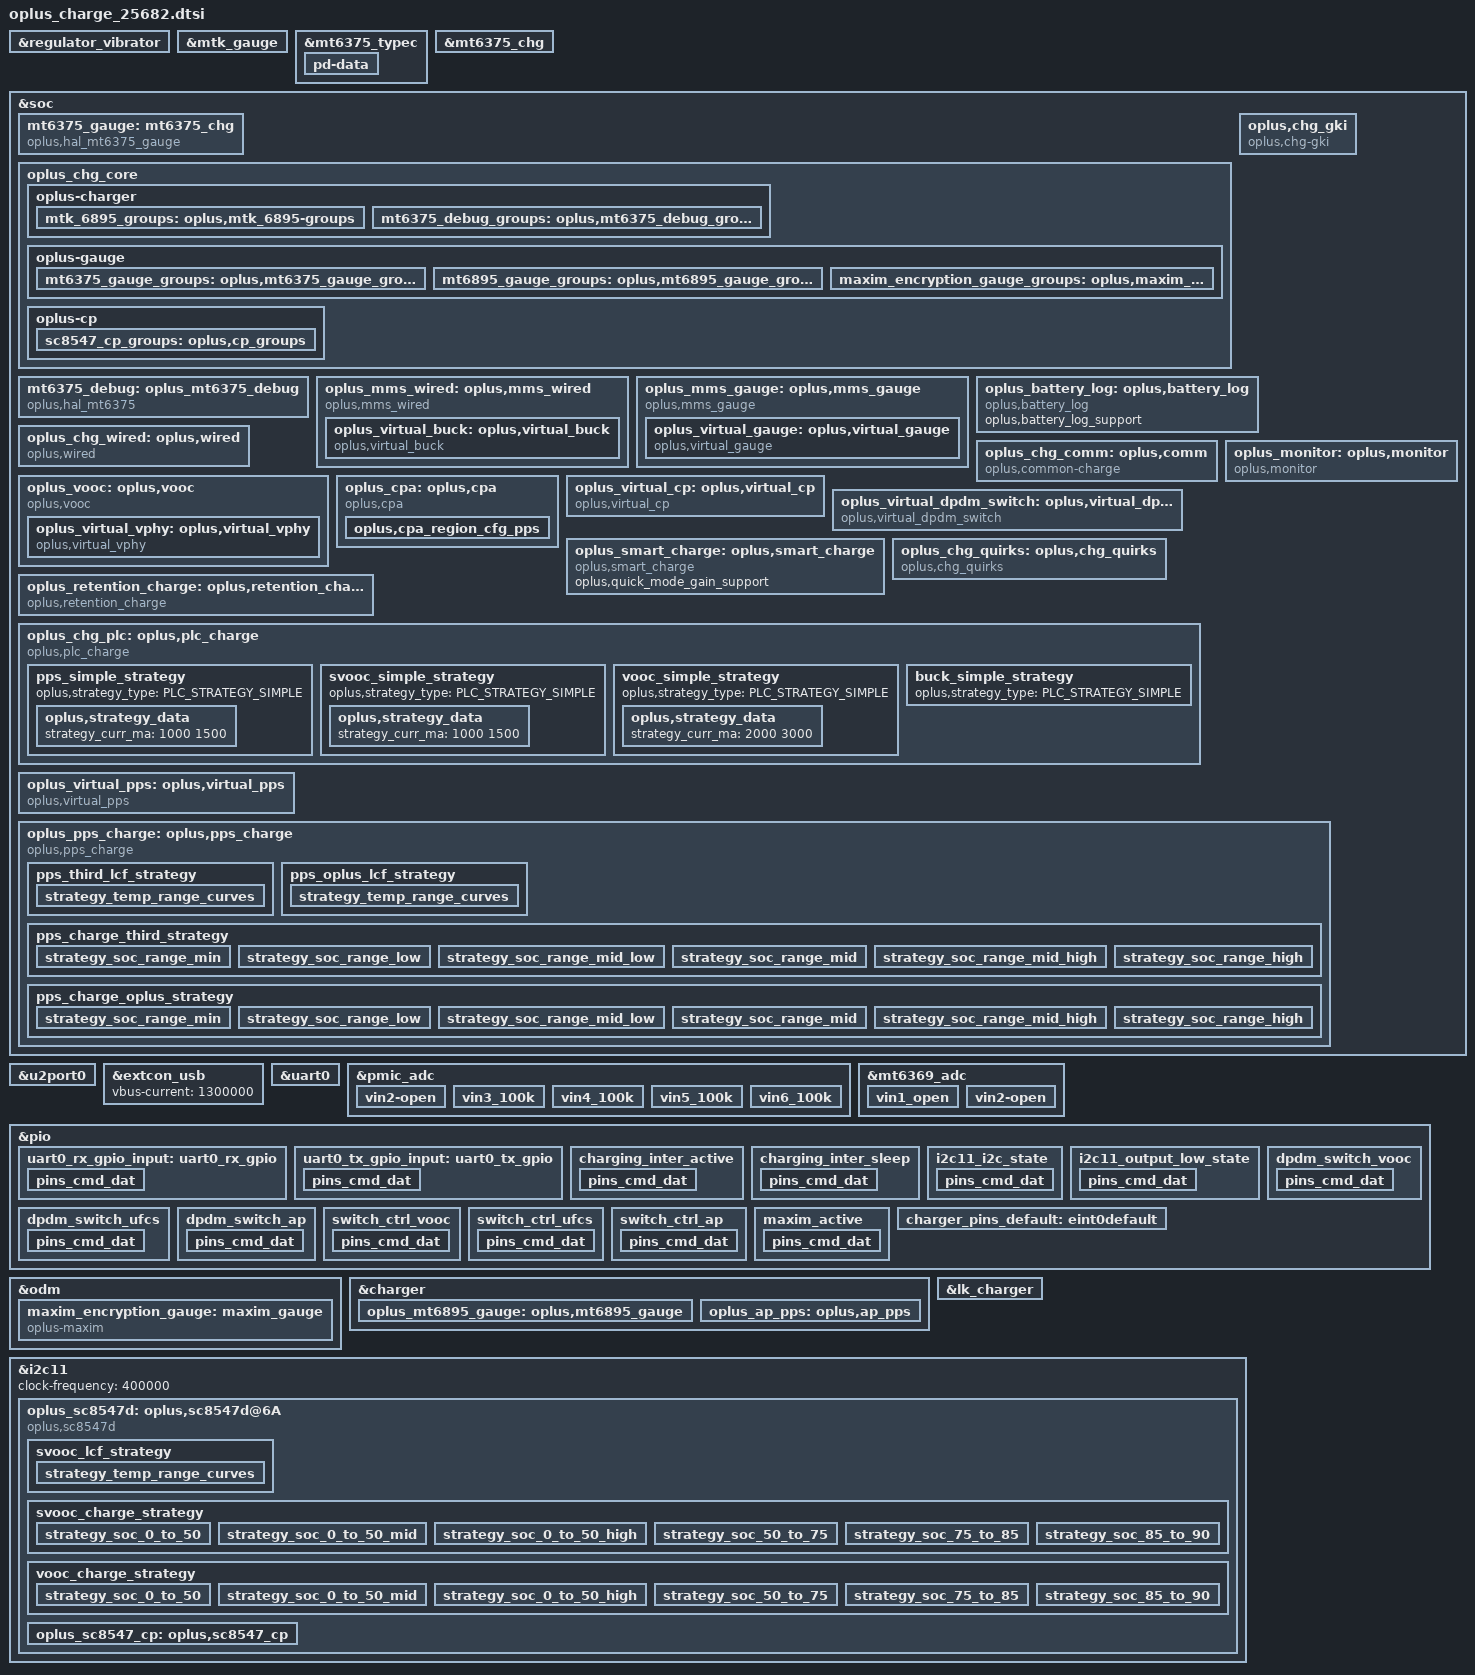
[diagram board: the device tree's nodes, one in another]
// SPDX-License-Identifier: GPL-2.0-only
/*
* Copyright (C) 2021-2020 Oplus. All rights reserved.
*/
#include <dt-bindings/iio/mt635x-auxadc.h>
#include <dt-bindings/iio/adc/mediatek,mt6375_auxadc.h>
#include <dt-bindings/pinctrl/mt6373-pinfunc.h>
#include <dt-bindings/pinctrl/mt65xx.h>
#include "oplus_chg.h"

/*
 *
 * CPU:MT6878 CHROME (export：CASIO-Y 24781，45W)
 *
 * UTXD0 -->GPIO48
 * URXD0 -->GPIO49
 *
 * I2C
 * MASTER_CHG --> I2C5 MT6375
 * CP_MASTER  --> I2C11 SC8547D
 * CP_SLAVE   --> I2C9 
 *
 * IRQB
 * EINT_CHG_1 (cp1 irq)               -->GPIO8
 * EINT_CHG_2 (cp2 irq)               -->GPIO9
 *
 * GPIO
 * VBUS_SHORT(防烧口)                 --> MT6369 MOS_CON1 H8
 * USB_SWITCH_1(usb/uart&vooc switch) --> GPIO44
 * USB_SWITCH_2(uart/vooc switch)     --> GPIO153
 * SEC_IC (加密电池GPIO for 80W)      --> GPIO43
 *
 * ADC:
 * MT6369 AUXADC_VIN1 				--> VBAT_BTB (Battery BTB)
 * MT6369 AUXADC_VIN2               --> NTC_USBCON_TEM (USB BTB)
 *
 * MT6363 AUXADC_VIN2				--> BAT_ID_ADC 电池ID
 * MT6363 AUXADC_VIN3				--> BATThermal_1 小板NTC
 * MT6363 AUXADC_VIN4				--> BB_USB_ADC1 防烧口NTC1
 * MT6363 AUXADC_VIN5				--> BB_USB_ADC2 防烧口NTC2
 * MT6363 AUXADC_VIN6				--> NTC_CHARGE (充电IC旁)
 *
 * BATTERY
 * BLT018 12200mAh double cells(NVT)  encrypted battery
 *
 */

/* charge start */
&regulator_vibrator{
	min-volt = <2800000>;
	max-volt = <2800000>;
};

&mtk_gauge {
	status = "okay";
	charger = <&mt6375_chg>;
	FUELGAGUE_APPLY = <(1)>;
	IS_SUBBOARD_TEMP_SUPPORT = <(0)>;
	EXTERNAL_AUTHENTICATE =<(1)>;
	Enable_Is_Force_Full = <(1)>;
	active-table = <(5)>;
	r-fg-value = <(2)>;/* R_sense resistance. 2 milliohm */
	com-r-fg-value = <(0)>;/* R_sense compensate resistance. not use COM_R_FG_VALUE */
	UNIT_MULTIPLE = <(1)>;
	RBAT_PULL_DOWN_R = <(24000)>;
	RBAT_PULL_UP_R = <(12000)>;
	RBAT_PULL_UP_VOLT = <(1840)>;
	USE_MORE_PRECISE_NTC_TABLE = <(1)>;
	car-tune-value = <(99)>;
	KEEP_100_PERCENT = <(1)>;
	SHUTDOWN_1_TIME = <(5)>;
	low-tmp-bat-voltage-low-bound1 = <(3350)>;
	com-fg-meter-resistance = <(40)>;

	io-channels = <&mt6375_auxadc MT6375_AUXADC_BATSNS>,
				  <&mt6375_auxadc MT6375_AUXADC_BATON>,
				  <&mt6375_auxadc MT6375_AUXADC_IMP>,
				  <&mt6375_auxadc MT6375_AUXADC_IMIX_R>,
				  <&mt6375_auxadc MT6375_AUXADC_VREF>,
				  <&pmic_adc (ADC_PURES_OPEN_MASK | AUXADC_VIN2)>;
	io-channel-names = "bat_volt", "bat_temp", "ptim_bat_volt",
					   "ptim_r", "vref", "auxadc5-batt_id_v";

	#include "bat_setting/mt6878_battery_prop_dim2_ext_25682_12200mAh_NVT.dtsi"
	#include "bat_setting/mt6878_battery_table_25682_12200mAh_NVT.dtsi"
};

&mt6375_typec {
	pd-data {
		pd,source-pdo-data = <0x00019082>; /* 5V, 1300 mA */
		pd,charging-policy = <0>;
	};
};

&mt6375_chg {
	ircmp_v = <0>;
	ircmp-r = <0>;
	chg-tmr = <15>;
};

&soc {
	mt6375_gauge: mt6375_chg {
		status = "okay";
		compatible = "oplus,hal_mt6375_gauge";

		oplus,ic_type = <OPLUS_CHG_IC_GAUGE>;
		oplus,ic_index = <0>;
		oplus,batt_num = <1>;
		oplus,mtk_gauge_power_sel_support;
		oplus,mtk_gauge_cali_track_support;
	};
};

&u2port0 {
	mediatek,eye-vrt = <7>;
	mediatek,eye-term = <7>;
	mediatek,rev6 = <3>;
	mediatek,eye-vrt-host = <7>;
	mediatek,eye-term-host = <7>;
	mediatek,rev6-host = <3>;
	mediatek,discth = <0x9>;
};

&extcon_usb {
	vbus-current = <1300000>;
};

&uart0 {
	pinctrl-names = "uart0_rx_gpio", "uart0_tx_gpio";
	pinctrl-0 = <&uart0_rx_gpio_input>;
	pinctrl-1 = <&uart0_tx_gpio_input>;
	status = "okay";
	txpin = <48>;
	rxpin = <49>;
};

&pmic_adc {
	vin2-open {
		channel = <AUXADC_VIN2>;
		pures = <ADC_PURES_OPEN>;
	};
	vin3_100k {
		channel = <AUXADC_VIN3>;
		pures = <ADC_PURES_100K>;
	};
	vin4_100k {
		channel = <AUXADC_VIN4>;
		pures = <ADC_PURES_100K>;
	};
	vin5_100k {
		channel = <AUXADC_VIN5>;
		pures = <ADC_PURES_100K>;
	};
	vin6_100k {
		channel = <AUXADC_VIN6>;
		pures = <ADC_PURES_100K>;
	};
};

&mt6369_adc {
    vin1_open {
		channel = <AUXADC_VIN1>;
		pures = <ADC_PURES_OPEN>;
    };
	vin2-open {
		channel = <AUXADC_VIN2>;
		pures = <ADC_PURES_OPEN>;
	};
};

&pio {
	uart0_rx_gpio_input: uart0_rx_gpio {
		pins_cmd_dat {
			pinmux = <PINMUX_GPIO49__FUNC_GPIO49>; /* URXD0 */
			input-enable;
			bias-disable;
		};
	};

	uart0_tx_gpio_input: uart0_tx_gpio {
		pins_cmd_dat {
			pinmux = <PINMUX_GPIO48__FUNC_GPIO48>; /* UTXD0 */
			input-enable;
			bias-disable;
		};
	};

	charging_inter_active: charging_inter_active {
		pins_cmd_dat {
			pinmux = <PINMUX_GPIO8__FUNC_GPIO8>;
			input-enable;
			bias-pull-up;
		};
	};

	charging_inter_sleep: charging_inter_sleep {
		pins_cmd_dat {
			pinmux = <PINMUX_GPIO8__FUNC_GPIO8>;
			input-enable;
			bias-pull-up;
		};
	};

	i2c11_i2c_state: i2c11_i2c_state {
		pins_cmd_dat {
			pinmux = <PINMUX_GPIO148__FUNC_SDA11>,
				 <PINMUX_GPIO147__FUNC_SCL11>;
			bias-disable;
		};
	};

	i2c11_output_low_state: i2c11_output_low_state {
		pins_cmd_dat {
			pinmux = <PINMUX_GPIO148__FUNC_GPIO148>,
				 <PINMUX_GPIO147__FUNC_GPIO147>;
			output-low;
		};
	};

	dpdm_switch_vooc: dpdm_switch_vooc {
		pins_cmd_dat {
			pinmux = <PINMUX_GPIO44__FUNC_GPIO44>;
			output-high;
		};
 	};

 	dpdm_switch_ufcs: dpdm_switch_ufcs {
 		pins_cmd_dat {
			pinmux = <PINMUX_GPIO44__FUNC_GPIO44>;
			output-high;
		};
 	};

 	dpdm_switch_ap: dpdm_switch_ap {
 		pins_cmd_dat {
			pinmux = <PINMUX_GPIO44__FUNC_GPIO44>;
			output-low;
		};
 	};

 	switch_ctrl_vooc: switch_ctrl_vooc {
 		pins_cmd_dat {
			pinmux = <PINMUX_GPIO153__FUNC_GPIO153>;
			output-high;
		};
 	};

 	switch_ctrl_ufcs: switch_ctrl_ufcs {
 		pins_cmd_dat {
			pinmux = <PINMUX_GPIO153__FUNC_GPIO153>;
			output-high;
		};
 	};

 	switch_ctrl_ap: switch_ctrl_ap {
 		pins_cmd_dat {
			pinmux = <PINMUX_GPIO153__FUNC_GPIO153>;
			output-low;
		};
 	};

	maxim_active: maxim_active {
		pins_cmd_dat {
			pinmux = <PINMUX_GPIO43__FUNC_GPIO43>;
			drive-strength = <6>;
			bias-pull-up;
		};
	};

	charger_pins_default: eint0default {
	};
};

&soc {
	oplus_chg_core {
		oplus,chg_framework_v2;
		oplus,smart_charging_screenoff;
		oplus,chg_spec_version = <OPLUS_CHG_SPEC_VER_V3P7>;
		oplus,common-charge-icl-support;
		oplus-charger {
			mtk_6895_groups: oplus,mtk_6895-groups {
				functions = <
					OPLUS_IC_FUNC_INIT
					OPLUS_IC_FUNC_EXIT
					OPLUS_IC_FUNC_REG_DUMP
					OPLUS_IC_FUNC_SMT_TEST
					OPLUS_IC_FUNC_BUCK_INPUT_PRESENT
					OPLUS_IC_FUNC_BUCK_INPUT_SUSPEND
					OPLUS_IC_FUNC_BUCK_INPUT_IS_SUSPEND
					OPLUS_IC_FUNC_BUCK_OUTPUT_SUSPEND
					OPLUS_IC_FUNC_BUCK_OUTPUT_IS_SUSPEND
					OPLUS_IC_FUNC_BUCK_SET_ICL
					OPLUS_IC_FUNC_BUCK_GET_ICL
					OPLUS_IC_FUNC_BUCK_SET_FCC
					OPLUS_IC_FUNC_BUCK_SET_FV
					OPLUS_IC_FUNC_BUCK_SET_ITERM
					OPLUS_IC_FUNC_BUCK_GET_INPUT_CURR
					OPLUS_IC_FUNC_BUCK_GET_INPUT_VOL
					OPLUS_IC_FUNC_OTG_BOOST_ENABLE
					OPLUS_IC_FUNC_BUCK_GET_CC_ORIENTATION
					OPLUS_IC_FUNC_BUCK_GET_CHARGER_TYPE
					OPLUS_IC_FUNC_BUCK_RERUN_BC12
					OPLUS_IC_FUNC_BUCK_QC_DETECT_ENABLE
					OPLUS_IC_FUNC_BUCK_SET_QC_CONFIG
					OPLUS_IC_FUNC_BUCK_SET_PD_CONFIG
					OPLUS_IC_FUNC_GET_SHUTDOWN_SOC
					OPLUS_IC_FUNC_BACKUP_SOC
					OPLUS_IC_FUNC_GET_TYPEC_MODE
					OPLUS_IC_FUNC_SET_TYPEC_MODE
					OPLUS_IC_FUNC_GET_TYPEC_ROLE
					OPLUS_IC_FUNC_GET_OTG_ENABLE
					OPLUS_IC_FUNC_BUCK_GET_HW_DETECT
					OPLUS_IC_FUNC_SET_USB_DISCHG_ENABLE
					OPLUS_IC_FUNC_GET_USB_DISCHG_STATUS
					OPLUS_IC_FUNC_IS_OPLUS_SVID
					OPLUS_IC_FUNC_BUCK_GET_USB_BTB_TEMP
					OPLUS_IC_FUNC_BUCK_GET_BATT_BTB_TEMP
					OPLUS_IC_FUNC_BUCK_SHIPMODE_ENABLE
					OPLUS_IC_FUNC_BUCK_SET_AICL_POINT
					OPLUS_IC_FUNC_SET_OTG_BOOST_CURR_LIMIT
					OPLUS_IC_FUNC_BUCK_GET_FV
					OPLUS_IC_FUNC_BUCK_GET_TYPEC_STATE
				>;
				virqs = <
					OPLUS_IC_VIRQ_ERR
					OPLUS_IC_VIRQ_CC_DETECT
					OPLUS_IC_VIRQ_PLUGIN
					OPLUS_IC_VIRQ_CC_CHANGED
					OPLUS_IC_VIRQ_CHG_TYPE_CHANGE
					OPLUS_IC_VIRQ_OTG_ENABLE
					OPLUS_IC_VIRQ_SVID
					OPLUS_IC_VIRQ_TYPEC_STATE
				>;
			};


			mt6375_debug_groups: oplus,mt6375_debug_groups {
				functions = <
					OPLUS_IC_FUNC_INIT
					OPLUS_IC_FUNC_EXIT
				>;
				virqs = <
					OPLUS_IC_VIRQ_ERR
				>;
			};
		};

		oplus-gauge {
			mt6375_gauge_groups: oplus,mt6375_gauge_groups {
				functions = <
					OPLUS_IC_FUNC_INIT
					OPLUS_IC_FUNC_EXIT
					OPLUS_IC_FUNC_REG_DUMP
					OPLUS_IC_FUNC_SMT_TEST
					OPLUS_IC_FUNC_GAUGE_GET_BATT_VOL
					OPLUS_IC_FUNC_GAUGE_GET_BATT_MAX
					OPLUS_IC_FUNC_GAUGE_GET_BATT_MIN
					OPLUS_IC_FUNC_GAUGE_GET_BATT_CURR
					OPLUS_IC_FUNC_GAUGE_GET_BATT_TEMP
					OPLUS_IC_FUNC_GAUGE_GET_BATT_SOC
					OPLUS_IC_FUNC_GAUGE_GET_BATT_FCC
					OPLUS_IC_FUNC_GAUGE_GET_BATT_CC
					OPLUS_IC_FUNC_GAUGE_GET_BATT_RM
					OPLUS_IC_FUNC_GAUGE_GET_BATT_SOH
					OPLUS_IC_FUNC_GAUGE_GET_BATT_HMAC
					OPLUS_IC_FUNC_GAUGE_SET_BATT_FULL
					OPLUS_IC_FUNC_GAUGE_UPDATE_DOD0
					OPLUS_IC_FUNC_GAUGE_UPDATE_SOC_SMOOTH
					OPLUS_IC_FUNC_GAUGE_GET_CB_STATUS
					OPLUS_IC_FUNC_GAUGE_GET_BATT_NUM
					OPLUS_IC_FUNC_GAUGE_GET_DEVICE_TYPE
					OPLUS_IC_FUNC_GAUGE_GET_DEVICE_TYPE_FOR_VOOC
					OPLUS_IC_FUNC_GAUGE_GET_BATT_FCC
					OPLUS_IC_FUNC_GAUGE_GET_BATT_FC
					OPLUS_IC_FUNC_GAUGE_GET_BATT_QM
					OPLUS_IC_FUNC_GAUGE_GET_BATT_PD
					OPLUS_IC_FUNC_GAUGE_GET_BATT_RCU
					OPLUS_IC_FUNC_GAUGE_GET_BATT_RCF
					OPLUS_IC_FUNC_GAUGE_GET_BATT_FCU
					OPLUS_IC_FUNC_GAUGE_GET_BATT_FCF
					OPLUS_IC_FUNC_GAUGE_GET_BATT_SOU
					OPLUS_IC_FUNC_GAUGE_GET_BATT_DO0
					OPLUS_IC_FUNC_GAUGE_GET_BATT_DOE
					OPLUS_IC_FUNC_GAUGE_GET_BATT_TRM
					OPLUS_IC_FUNC_GAUGE_GET_BATT_PC
					OPLUS_IC_FUNC_GAUGE_GET_BATT_QS
					OPLUS_IC_FUNC_GAUGE_IS_SUSPEND
					OPLUS_IC_FUNC_GAUGE_GET_BCC_PARMS
					OPLUS_IC_FUNC_GAUGE_FASTCHG_UPDATE_BCC_PARMS
					OPLUS_IC_FUNC_GAUGE_GET_PREV_BCC_PARMS
					OPLUS_IC_FUNC_GAUGE_SET_BCC_PARMS
					OPLUS_IC_FUNC_GAUGE_SET_PROTECT_CHECK
					OPLUS_IC_FUNC_GAUGE_GET_AFI_UPDATE_DONE
					OPLUS_IC_FUNC_GAUGE_CHECK_RESET
					OPLUS_IC_FUNC_GAUGE_GET_DEVICE_TYPE_FOR_BCC
					OPLUS_IC_FUNC_GAUGE_GET_DOD0
					OPLUS_IC_FUNC_GAUGE_GET_DOD0_PASSED_Q
					OPLUS_IC_FUNC_GAUGE_GET_QMAX
					OPLUS_IC_FUNC_GAUGE_GET_QMAX_PASSED_Q
					OPLUS_IC_FUNC_GAUGE_SET_BATTERY_CURVE
					OPLUS_IC_FUNC_GAUGE_GET_DEC_FG_TYPE
					OPLUS_IC_FUNC_GAUGE_GET_DEC_CV_SOH
				>;
				virqs = <
					OPLUS_IC_VIRQ_ERR
					OPLUS_IC_VIRQ_OFFLINE
					OPLUS_IC_VIRQ_RESUME
				>;
			};

			mt6895_gauge_groups: oplus,mt6895_gauge_groups {
				functions = <
					OPLUS_IC_FUNC_INIT
					OPLUS_IC_FUNC_EXIT
					OPLUS_IC_FUNC_GAUGE_GET_SUBBOARD_TEMP
				>;
				virqs = <
					OPLUS_IC_VIRQ_ERR
				>;
			};

			maxim_encryption_gauge_groups: oplus,maxim_encryption_gauge_groups {
				functions = <
					OPLUS_IC_FUNC_INIT
					OPLUS_IC_FUNC_EXIT
					OPLUS_IC_FUNC_GAUGE_GET_BATT_AUTH
				>;
				virqs = <
					OPLUS_IC_VIRQ_ERR
				>;
			};
		};
		oplus-cp {
			sc8547_cp_groups: oplus,cp_groups {
			functions = <
					OPLUS_IC_FUNC_INIT
					OPLUS_IC_FUNC_EXIT
					OPLUS_IC_FUNC_REG_DUMP
					OPLUS_IC_FUNC_SMT_TEST
					OPLUS_IC_FUNC_CP_ENABLE
					OPLUS_IC_FUNC_CP_HW_INTI
					OPLUS_IC_FUNC_CP_SET_WORK_START
					OPLUS_IC_FUNC_CP_CHECK_WORK_MODE_SUPPORT
					OPLUS_IC_FUNC_CP_SET_WORK_MODE
					OPLUS_IC_FUNC_CP_GET_WORK_MODE
					OPLUS_IC_FUNC_CP_GET_VIN
					OPLUS_IC_FUNC_CP_GET_IIN
					OPLUS_IC_FUNC_CP_SET_IIN
					OPLUS_IC_FUNC_CP_GET_VOUT
					OPLUS_IC_FUNC_CP_GET_IOUT
					OPLUS_IC_FUNC_CP_GET_VAC
					OPLUS_IC_FUNC_CP_GET_WORK_STATUS
					OPLUS_IC_FUNC_CP_SET_ADC_ENABLE
					OPLUS_IC_FUNC_CP_WATCHDOG_ENABLE
					OPLUS_IC_FUNC_CP_SET_UCP_DISABLE
				>;
				virqs = <
					OPLUS_IC_VIRQ_ERR
					OPLUS_IC_VIRQ_ONLINE
					OPLUS_IC_VIRQ_OFFLINE
				>;
			};
		};
	};
};

&soc {
	mt6375_debug: oplus_mt6375_debug {
		status = "okay";
		compatible = "oplus,hal_mt6375";
		oplus,tcpc_name = "type_c_port0";
		oplus,ic_type = <OPLUS_CHG_IC_BUCK>;
		oplus,ic_index = <2>;
	};
};

/*
* chrome secbat sn
* 6113 0700 0087
* 6113 0700 0088
* 6129 0300 0144
* 6113 0300 0213
*/
&odm {
	maxim_encryption_gauge: maxim_gauge {
		status = "okay";
		compatible = "oplus-maxim";
		pinctrl-names = "maxim_active";
		pinctrl-0 = <&maxim_active>;
		support_encryption_in_lk;
		data-gpio = <&pio 43 0x00>;
		gpio-addr-set-out = <0x10005014>;
		gpio-addr-set-in = <0x10005018>;
		gpio-addr-level_high = <0x10005114>;
		gpio-addr-level_low = <0x10005118>;
		gpio-addr-data-in = <0x10005210>;
		gpio-addr-offset = <0x0b>;
		oplus,batt_info = /bits/ 8 <0x36 0x31 0x31 0x33 0x30 0x37 0x30 0x30 0x30 0x30 0x38 0x37
		                            0x36 0x31 0x31 0x33 0x30 0x37 0x30 0x30 0x30 0x30 0x38 0x38
		                            0x36 0x31 0x32 0x39 0x30 0x33 0x30 0x30 0x30 0x31 0x34 0x34
		                            0x36 0x31 0x31 0x33 0x30 0x33 0x30 0x30 0x30 0x32 0x31 0x33>;
		oplus,ic_type = <OPLUS_CHG_IC_GAUGE>;
		oplus,ic_index = <2>;
	};
};

&soc {
	oplus,chg_gki {
		compatible = "oplus,chg-gki";
	};
};

&charger {
	io-channels = <&mt6369_adc (ADC_PURES_OPEN_MASK | AUXADC_VIN1)>, <&mt6369_adc (ADC_PURES_OPEN_MASK | AUXADC_VIN2)>, <&pmic_adc AUXADC_VIN6>, <&pmic_adc AUXADC_VIN3>;
	io-channel-names = "auxadc5_batt_btb_temp", "auxadc6_usb_btb_temp", "auxadc5-chargeric_temp", "auxadc1-ntc_sub_bat_tem";

	pinctrl-names = "default";
	pinctrl-0 = <&charger_pins_default>;
	oplus,support_ntc_01c_precision;
	max_charger_voltage = <15000000>;
	oplus,ntc_temp_volt_1840mv;
	oplus,force_use_4250K_ntc;

	/* usbtemp dischg use pmic regulator to set vbus down */
	oplus,support_usbtemp_dischg_reg_configurable;
	oplus,usbtemp_dischg_reg_addr = <0x989>;
	oplus,usbtemp_dischg_reg_mask = <0x7>;
	oplus,usbtemp_dischg_enable = <0x2>;
	oplus,usbtemp_dischg_disable = <0x0>;

	oplus,ic_type = <OPLUS_CHG_IC_BUCK>;
	oplus,ic_index = <0>;

	oplus_mt6895_gauge: oplus,mt6895_gauge {
		oplus,ic_type = <OPLUS_CHG_IC_GAUGE>;
		oplus,ic_index = <1>;
	};
};

&lk_charger {
	en_vol_ctrl_vibrate = <3200>;
	support_tuv_authentication;
	high-temp-scheme;
	charger_no_wiress;
	support_battery_type = <2>;
	support_maxim_battery_authentication;
	data-gpio = <43>;
	oplus,batt_info = /bits/ 8 <0x36 0x31 0x31 0x33 0x30 0x37 0x30 0x30 0x30 0x30 0x38 0x37
		                        0x36 0x31 0x31 0x33 0x30 0x37 0x30 0x30 0x30 0x30 0x38 0x38
		                        0x36 0x31 0x32 0x39 0x30 0x33 0x30 0x30 0x30 0x31 0x34 0x34
		                        0x36 0x31 0x31 0x33 0x30 0x33 0x30 0x30 0x30 0x32 0x31 0x33>;

	support_sdp_screenoff;
	support_sdp_backlight;
	sdp_screenon_voltage = <3250>;
	support_quickboot_charge;
	over_high_temp_thr = <60>;
	led-brightness = <102>;
	max-charger-voltage = <15000000>;
	boot-battery-voltage = <3350000>;
	usb-charger-current = <500000>;
	ac-charger-current = <2050000>;
	ac-charger-input-current = <1500000>;
	non-std-ac-charger-current = <750000>;
	charging-host-charger-current = <1500000>;
	ta-ac-charger-current = <1500000>;
	pd-charger-current = <500000>;
};

&soc {
	oplus_mms_wired: oplus,mms_wired {
		compatible = "oplus,mms_wired";
		oplus,buck_ic = <&oplus_virtual_buck>;
		oplus,voocphy_ic = <&oplus_virtual_vphy>;
		oplus,adc_info_name = "100k_1840mv";
		oplus_spec,usbtemp_batttemp_gap = <12>;

		/* support for V2.0 usbtemp protect. */
		high-temp-scheme;
		oplus,support_usbtemp_protect_v2;
		oplus_spec,usbtemp_batt_temp_low = <50>;
		oplus_spec,usbtemp_batt_temp_high = <50>;
		oplus_spec,usbtemp_batt_temp_over_hot = <60>;
		oplus_spec,usbtemp_ntc_temp_low = <57>;
		oplus_spec,usbtemp_ntc_temp_high = <69>;
		oplus_spec,usbtemp_temp_gap_low_with_batt_temp = <7>;
		oplus_spec,usbtemp_temp_gap_with_batt_temp_in_over_hot = <15>;
		oplus_spec,usbtemp_temp_gap_high_with_batt_temp = <12>;
		oplus_spec,usbtemp_temp_gap_low_without_batt_temp = <12>;
		oplus_spec,usbtemp_temp_gap_high_without_batt_temp = <24>;
		oplus_spec,usbtemp_rise_fast_temp_low = <3>;
		oplus_spec,usbtemp_rise_fast_temp_high = <3>;
		oplus_spec,usbtemp_rise_fast_temp_count_low = <30>;
		oplus_spec,usbtemp_rise_fast_temp_count_high = <20>;
		oplus_spec,usbtemp_cool_down_ntc_low = <54>;
		oplus_spec,usbtemp_cool_down_ntc_high = <65>;
		oplus_spec,usbtemp_cool_down_gap_low = <12>;
		oplus_spec,usbtemp_cool_down_gap_high = <20>;
		oplus_spec,usbtemp_cool_down_recover_ntc_low = <48>;
		oplus_spec,usbtemp_cool_down_recover_ntc_high = <60>;
		oplus_spec,usbtemp_cool_down_recover_gap_low = <6>;
		oplus_spec,usbtemp_cool_down_recover_gap_high = <15>;
		oplus_spec,usbtemp_otg_cc_boot_current_limit = <1300000>;

		oplus_virtual_buck: oplus,virtual_buck {
			compatible = "oplus,virtual_buck";
			oplus,buck_ic = <&charger &mt6375_debug>;
			oplus,buck_ic_index = <0 1>;
			oplus,buck_ic_current_ratio = <100 0>;
			oplus,buck_ic_connect = <OPLUS_CHG_IC_CONNECT_PARALLEL>;
			oplus,main_charger = <0>;
			oplus,buck_ic_func_group = <&mtk_6895_groups &mt6375_debug_groups>;

			oplus,ic_type = <OPLUS_CHG_IC_VIRTUAL_BUCK>;
			oplus,ic_index = <0>;

			io-channels = <&pmic_adc AUXADC_VIN4>, <&pmic_adc AUXADC_VIN5>;
			io-channel-names = "usb_temp_adc_l", "usb_temp_adc_r";

			oplus,uart_tx-gpio = <&pio 48 0x00>;
			oplus,uart_rx-gpio = <&pio 49 0x00>;
		};
	};

	oplus_mms_gauge: oplus,mms_gauge {
		compatible = "oplus,mms_gauge";
		oplus,gauge_ic = <&oplus_virtual_gauge>;
		oplus,voocphy_ic = <&oplus_virtual_vphy>;
		oplus,topic-update-interval = <10000>;

		oplus_virtual_gauge: oplus,virtual_gauge {
			compatible = "oplus,virtual_gauge";
			oplus,gauge_ic = <&mt6375_gauge &oplus_mt6895_gauge &maxim_encryption_gauge>;
			oplus,gauge_ic_index = <0 1 2>;
			oplus,gauge_ic_func_group = <&mt6375_gauge_groups &mt6895_gauge_groups &maxim_encryption_gauge_groups>;
			oplus,batt_capacity_mah = <12200>;
			oplus,ic_type = <OPLUS_CHG_IC_VIRTUAL_GAUGE>;
			oplus,ic_index = <0>;
		};
	};
};

&soc {
	oplus_battery_log: oplus,battery_log {
		compatible = "oplus,battery_log";
		oplus,battery_log_support;
	};

	oplus_chg_wired: oplus,wired {
		compatible = "oplus,wired";

		oplus,vooc-support;
		oplus_spec,vbatt_pdqc_to_5v_thr = <4490>;
		oplus_spec,vbatt_pdqc_to_9v_thr = <4500>;
		oplus_spec,pd-iclmax-ma = <1500>;
		oplus_spec,qc-iclmax-ma = <1500>;
		oplus_spec,non-standard-ibatmax-ma = <500>;
		oplus_spec,input-power-mw = <
			2500		/* OPLUS_WIRED_CHG_MODE_UNKNOWN */
			2500		/* OPLUS_WIRED_CHG_MODE_SDP */
			7500		/* OPLUS_WIRED_CHG_MODE_CDP */
			10000		/* OPLUS_WIRED_CHG_MODE_DCP */
			15000		/* OPLUS_WIRED_CHG_MODE_VOOC */
			13500		/* OPLUS_WIRED_CHG_MODE_QC */
			13500		/* OPLUS_WIRED_CHG_MODE_PD */
		>;
		oplus_spec,led_on-fccmax-ma = <0 1140 4000 4000 4000 4000 4000 1000 0>;
		oplus_spec,fccmax-ma-lv = <
			0 600   2200 2200 2200 2200 2200 2200 0	/* OPLUS_WIRED_CHG_MODE_UNKNOWN */
			0 600   600  600  600  600  600  600  0	/* OPLUS_WIRED_CHG_MODE_SDP */
			0 600   1600 1600 1600 1600 1600 1600 0	/* OPLUS_WIRED_CHG_MODE_CDP */
			0 600   2200 2200 2200 2200 2200 2200 0	/* OPLUS_WIRED_CHG_MODE_DCP */
			0 600   3000 3000 3000 3000 3000 2200 0	/* OPLUS_WIRED_CHG_MODE_VOOC */
			0 600   3300 3300 3300 3300 3300 3300 0	/* OPLUS_WIRED_CHG_MODE_QC */
			0 600   3300 3300 3300 3300 3300 3300 0	/* OPLUS_WIRED_CHG_MODE_PD */
		>;
		oplus_spec,fccmax-ma-hv = <
			0 600   2200 2200 2200 2200 2200 2200 0	/* OPLUS_WIRED_CHG_MODE_UNKNOWN */
			0 600   600  600  600  600  600  600  0	/* OPLUS_WIRED_CHG_MODE_SDP */
			0 600   1600 1600 1600 1600 1600 1600 0	/* OPLUS_WIRED_CHG_MODE_CDP */
			0 600   2200 2200 2200 2200 2200 2200 0	/* OPLUS_WIRED_CHG_MODE_DCP */
			0 600   3000 3000 3000 3000 3000 2200 0	/* OPLUS_WIRED_CHG_MODE_VOOC */
			0 600   3300 3300 3300 3300 3300 3300 0	/* OPLUS_WIRED_CHG_MODE_QC */
			0 600   3300 3300 3300 3300 3300 3300 0	/* OPLUS_WIRED_CHG_MODE_PD */
		>;
		oplus_spec,cool_down_sale_pdqc_vol_mv = <5000>;
		oplus_spec,cool_down_pdqc_vol_mv = <5000 5000 5000 9000>;
		oplus_spec,cool_down_pdqc_curr_ma = <1200 1500 2000 1500>;
		oplus_spec,cool_down_vooc_curr_ma = <1200 1500 2000 2500 3000 3000>;
		oplus_spec,cool_down_normal_curr_ma = <1200 1500 2000>;

		oplus_spec,vbus_ov_thr_mv = <10500 10500>;
		oplus_spec,vbus_uv_thr_mv = <4300 4300>;

		oplus,pd_strategy_name = "cgcl";
		oplus,pd_strategy_data = <OPLUS_STRATEGY_USE_SHELL_TEMP
					    0   420 2000 1 0
					    420 430 1500 2 0
					    450 440 1200 2 1>;
		oplus,qc_strategy_name = "cgcl";
		oplus,qc_strategy_data = <OPLUS_STRATEGY_USE_SHELL_TEMP
					    0   420 2000 1 0
					    410 430 1500 2 0
					    420 440 1200 2 1>;
	};

	oplus_chg_comm: oplus,comm {
		compatible = "oplus,common-charge";
		oplus_spec,dec_step = <20>;
		oplus_spec,dec-vol-cc-full-thr = <0 400 600 800 1000 1200>;
		oplus_spec,dec-vol-fv-full-mv = <0 20 20 40 40 40>;
		oplus_spec,batt-them-thr = <(-100) 0 50 120 160 350 450 530>;
		oplus_spec,iterm-ma = <605>; /* 12200*0.05+10 */
		oplus_spec,removed_bat_decidegc = <390>; /*-39 degree*/
		oplus_spec,fv-mv = <4490 4490 4490 4490 4490 4490 4470 4130 4130>;
		oplus_spec,sw-fv-mv = <4440 4440 4440 4440 4440 4440 4420 4080 4080>;
		oplus_spec,hw-fv-inc-mv = <0 18 18 18 18 18 18 18 0>;
		oplus_spec,sw-over-fv-mv = <4500 4500 4500 4500 4500 4500 4480 4140 4140>;
		oplus_spec,sw-over-fv-dec-mv = <8>;
		oplus_spec,non-standard-sw-fv-mv = <3930>;
		oplus_spec,non-standard-fv-mv = <3980>;
		oplus_spec,non-standard-hw-fv-inc-mv = <18>;
		oplus_spec,non-standard-sw-over-fv-mv = <3990>;
		oplus_spec,non-standard-vbatdet-mv = <3680>;
		oplus_spec,wired-vbatdet-mv = <0 4190 4290 4390 4390 4390 4370 4030 0>;
		oplus_spec,fcc-gear-thr-mv = <4180>;
		oplus_spec,vbatt-ov-thr-mv = <4600>;

		oplus_spec,full_pre_ffc_judge;
		oplus_spec,full-pre-ffc-mv = <4485>;
		oplus_spec,ffc-temp-thr = <120 210 350 440>;
		oplus_spec,wired-ffc-step-max = <2>;
		oplus_spec,wired-ffc-fv-mv = <4630 4630>;

		oplus_spec,wired-ffc-fv-cutoff-mv = <4494 4494 4474 4484 4484 4465>;
		oplus_spec,wired-ffc-fcc-ma = <1500 1500 1500 1000 1000 1000>;
		oplus_spec,wired-ffc-fcc-cutoff-ma = <1300 1300 1300 900 900 900>;
		oplus_spec,vbat_uv_thr_mv = <3300>;
		oplus_spec,vbat_charging_uv_thr_mv = <3200>;

		/*If use subboard NTC as battery temp, config it as 20, otherwise 0 */
		oplus_spec,tbatt_power_off_cali_temp = <0>;
		oplus_spec,poweroff_high_batt_temp = <720>;
		oplus_spec,poweroff_emergency_batt_temp = <770>;
		oplus,vooc_show_ui_soc_decimal;
		oplus,ui_soc_decimal_speedmin = <20>;
		oplus,gauge_stuck_jump_support;
		oplus,gauge_stuck_threshold = <15>;
		oplus,gauge_stuck_time = <50>;
		oplus,smooth_switch;
		oplus,reserve_chg_soc = <2>;
	};

	oplus_monitor: oplus,monitor {
		compatible = "oplus,monitor";
		oplus,topic-update-interval = <60000>;

		track,fast_chg_break_t_thd = <1000>;
		track,general_chg_break_t_thd = <200>;
		track,voocphy_type = <2>;
		track,wired_max_power = <45000>;
		track,wired_fast_chg_scheme = <2>;
	};

	oplus_vooc: oplus,vooc {
		compatible = "oplus,vooc";
		oplus,vooc_ic = <&oplus_virtual_vphy>;
		oplus_spec,vooc_soc_range = <50 75 85>;
		oplus,vooc_data_width = <7>;
		oplus,vooc_curr_max = <CP_CURR_LIMIT_7BIT_9_0A>; /* 45W: 11V 7.3A(IBUS *2) */
		oplus,vooc_power_max_w = <45>;
		oplus,vooc_project = <21>;
		oplus,vooc_curr_table_type = <VOOC_CP_CURR_TABLE>;
		oplus,voocphy_support = <2>; /* AP_SINGLE_CP_VOOCPHY */
		oplus,support_fake_vooc_check;
		oplus,subboard_ntc_abnormal_current = <4000>;

		oplus,abnormal_adapter_current = <CURR_LIMIT_7BIT_7_5A CURR_LIMIT_7BIT_7_5A
						CURR_LIMIT_7BIT_5_0A CURR_LIMIT_7BIT_5_0A
						CURR_LIMIT_7BIT_4_0A CURR_LIMIT_7BIT_4_0A
						CURR_LIMIT_7BIT_3_0A CURR_LIMIT_7BIT_3_0A
						CURR_LIMIT_7BIT_2_0A CURR_LIMIT_7BIT_2_0A>;

		oplus,general_strategy_name = "cgcl";
		oplus,general_strategy_data = < OPLUS_STRATEGY_USE_SHELL_TEMP
						0   385 CP_CURR_LIMIT_7BIT_9_0A 1 0
						375 405 CP_CURR_LIMIT_7BIT_7_0A 2 0
						395 420 CP_CURR_LIMIT_7BIT_5_0A 3 1
						410 430 CP_CURR_LIMIT_7BIT_4_0A 4 2
						425 440 CP_CURR_LIMIT_7BIT_3_0A 4 3 >;

		oplus,plc_strategy-data = <&buck_simple_strategy &svooc_simple_strategy &vooc_simple_strategy>;
		oplus,plc_strategy-names = "default", "svooc", "vooc";

		oplus_virtual_vphy: oplus,virtual_vphy {
			compatible = "oplus,virtual_vphy";
			oplus,vphy_ic = <&oplus_sc8547d>;

			oplus,ic_type = <OPLUS_CHG_IC_VIRTUAL_VPHY>;
			oplus,ic_index = <0>;
			oplus,dpdm_switch_ic = <&oplus_virtual_dpdm_switch>;
		};
	};

	oplus_cpa: oplus,cpa {
		compatible = "oplus,cpa";
		oplus,protocol_list = <CHG_PROTOCOL_VOOC 45
				       CHG_PROTOCOL_PPS  45
				       CHG_PROTOCOL_PD 15>;
		oplus,default_protocol_list = <CHG_PROTOCOL_VOOC
						CHG_PROTOCOL_PPS
						CHG_PROTOCOL_PD>;
	};

	oplus_virtual_cp: oplus,virtual_cp {
		compatible = "oplus,virtual_cp";

		oplus,ic_type = <OPLUS_CHG_IC_VIRTUAL_CP>;
		oplus,ic_index = <0>;

		oplus,cp_ic = <&oplus_sc8547_cp>;
		oplus,input_curr_max_ma = <5000>;
		oplus,main_cp = <0>;
		oplus,cp_ic_connect = <OPLUS_CHG_IC_CONNECT_PARALLEL>;

		oplus,reg_proc_node;
	};

	oplus_virtual_dpdm_switch: oplus,virtual_dpdm_switch {
		compatible = "oplus,virtual_dpdm_switch";
		oplus,ic_type = <OPLUS_CHG_IC_MISC>;
		oplus,ic_index = <0>;

		oplus,switch_ctrl-gpio = <&pio 153 0x00>;
		oplus,dpdm_switch1-gpio = <&pio 44 0x00>;

		pinctrl-names = "switch_ctrl_ap", "switch_ctrl_vooc", "switch_ctrl_ufcs",
						"dpdm_switch_ap", "dpdm_switch_vooc", "dpdm_switch_ufcs";
		pinctrl-0 = <&switch_ctrl_ap>;
		pinctrl-1 = <&switch_ctrl_vooc>;
		pinctrl-2 = <&switch_ctrl_ufcs>;
		pinctrl-3 = <&dpdm_switch_ap>;
		pinctrl-4 = <&dpdm_switch_vooc>;
		pinctrl-5 = <&dpdm_switch_ufcs>;
	};
	oplus_smart_charge: oplus,smart_charge {
		compatible = "oplus,smart_charge";
		oplus,quick_mode_gain_support;
	};
	oplus_chg_quirks: oplus,chg_quirks {
		compatible = "oplus,chg_quirks";
	};
	oplus_retention_charge: oplus,retention_charge {
		compatible = "oplus,retention_charge";
		oplus,topic-update-interval = <5000>;
		oplus,support_retention_name = "oplus_retention_quirks";
	};
};

&soc {
	oplus_chg_plc: oplus,plc_charge {
		compatible = "oplus,plc_charge";
		oplus,plc_support = <CHG_PROTOCOL_UFCS>;
		oplus,plc_soc = <90>;
		oplus,plc_support_timeout;
		oplus,plc_strategy-data = <&buck_simple_strategy>;
		oplus,plc_strategy-names = "default";

		pps_simple_strategy: pps_simple_strategy {
			oplus,strategy_type = <PLC_STRATEGY_SIMPLE>;
			oplus,strategy_data {
				strategy_curr_ma = <1000 1500>;
			};
		};

		svooc_simple_strategy: svooc_simple_strategy {
			oplus,strategy_type = <PLC_STRATEGY_SIMPLE>;
			oplus,strategy_data {
				strategy_curr_ma = <1000 1500>;
			};
		};

		vooc_simple_strategy: vooc_simple_strategy {
			oplus,strategy_type = <PLC_STRATEGY_SIMPLE>;
			oplus,strategy_data {
				strategy_curr_ma = <2000 3000>;
			};
		};

		buck_simple_strategy: buck_simple_strategy {
			oplus,strategy_type = <PLC_STRATEGY_SIMPLE>;
		};
	};
};

&i2c11 {
	status = "okay";
	clock-frequency = <400000>;
	oplus_sc8547d: oplus,sc8547d@6A {
		status = "okay";
		compatible = "oplus,sc8547d";
		reg = <0x6A>;

		oplus,use_vooc_phy;
		oplus_spec,irq_gpio = <&pio 8 0x00>;
		interrupt-parent = <&pio>;
		interrupts = <9 0>;

		pinctrl-names = "charging_inter_active", "charging_inter_sleep", "i2c-state", "output-low-state";
		pinctrl-0 = <&charging_inter_active>;
		pinctrl-1 = <&charging_inter_sleep>;
		pinctrl-2 = <&i2c11_i2c_state>;
		pinctrl-3 = <&i2c11_output_low_state>;

		oplus,ic_type = <OPLUS_CHG_IC_VPHY>;
		oplus,ic_index = <0>;
		oplus,vooc-version = <VOOC_VERSION_5_0>;

		ocp_reg = <0xe>;
		ovp_reg = <0x36>;/* vbat ovp 4.85v */
		vbus_ovp_reg = /bits/ 8 <0x5A>;/* vbus ovp 11.5v */
		oplus_spec,slave_cp_enable_thr = <1400>;		//2000-100mA
		oplus_spec,slave_cp_disable_thr_high = <1100>;	//1500+100mA
		oplus_spec,voocphy_current_default = <73>;

		oplus_spec,svooc_cool_down_current_limit = <82 20 20 24 30 34 40 44 50 54 60 64 70 74>;
		oplus_spec,vooc_cool_down_current_limit = <30 20 20 24 30 34 40 44 50 54 60 64 70 74>;

		oplus_spec,vooc_low_temp = <0>;
		oplus_spec,vooc_little_cold_temp = <50>;
		oplus_spec,vooc_cool_temp = <120>;
		oplus_spec,vooc_little_cool_temp = <160>;
		oplus_spec,vooc_little_cool_high_temp = <210>;
		oplus_spec,vooc_normal_low_temp = <350>;
		oplus_spec,vooc_normal_high_temp = <440>;
		oplus_spec,vooc_high_temp = <500>;
		oplus_spec,vooc_over_high_temp = <510>;
		oplus_spec,vooc_strategy_normal_current = <122>;
		oplus_spec,vooc_normal_to_little_cool_current = <100>;
		oplus_spec,vooc_multistep_initial_batt_temp = <1000>;
		oplus_spec,fastchg_timeout_time_init = <306120>;

		oplus_spec,vooc_low_soc = <0>;
		oplus_spec,vooc_high_soc = <95>;
		oplus_spec,vooc_warm_vol_thr = <4000>;
		oplus_spec,vooc_warm_soc_thr = <55>;

		oplus_spec,voocphy_freq_mincore = <1800000>;
		oplus_spec,voocphy_freq_midcore = <1800000>;
		oplus_spec,voocphy_freq_maxcore = <1800000>;
		oplus_spec,voocphy_current_change_timeout = <100>;
		oplus_spec,copycat_vooc_support;
		oplus_spec,copycat_vooc_accuracy_value = <105>;
		oplus,copycat-vooc-count = <4>;

		oplus_spec,voocphy_ibat_over_current = <9600>;
		oplus_spec,voocphy_svooc_cp_max_ibus = <4500>;
		oplus_spec,voocphy_vooc_cp_max_ibus = <4500>;
		oplus_spec,voocphy_cp_max_ibus = <4500>;

		oplus,workaround_for_100w;
		oplus_spec,vooc_little_cold_full_voltage = <4510>;
		oplus_spec,vooc_cool_full_voltage = <4510>;
		oplus_spec,vooc_little_cool_full_voltage = <4545>;
		oplus_spec,vooc_little_cool_high_full_voltage = <4545>;
		oplus_spec,vooc_warm_full_voltage = <4130>;
		oplus_spec,vooc_1time_full_voltage = <4555>;
		oplus_spec,vooc_ntime_full_voltage = <4545>;
		oplus_spec,full_voltage = < /* vol_1time vol_ntime */
					4520 4510 /* 0 ~ 5 */
					4520 4510 /* 5 ~ 12 */
					4555 4545 /* 12 ~ 16 */
					4555 4545 /* 16 ~ 20 */
					4555 4545 /* 20 ~ 35 */
					4555 4545 /* 35 ~ 44 */
					4140 4130 /* 44 ~ 51 */
					>;
		oplus_spec,soc_range = <0 20 35 55 75 85 95>;

		svooc_batt_sys_curve = <0 1 0 1 0 0 0	// 4000mA
					1 1 1 1 0 0 0	// 4604mV
					0 0 1 1 0 1 0	// 2600mA
					1 1 1 1 0 0 0	// 4604mV
					0 0 0 1 0 1 1	// 1100mA
					1 1 1 1 0 0 0>;	// 4604mV

		vooc_batt_sys_curve =  <0 1 0 1 0 0 0	// 4000mA
					1 1 1 1 0 0 0	// 4604mV
					0 0 1 1 0 1 0	// 2600mA
					1 1 1 1 0 0 0	// 4604mV
					0 0 0 1 0 1 1	// 1100mA
					1 1 1 1 0 0 0>;	// 4604mV

		svooc_lcf_strategy {
			oplus,temp_type = <OPLUS_STRATEGY_USE_SHELL_TEMP>;
			oplus,temp_range = <0 50 120 160 210 380 440>;

			strategy_temp_range_curves {
				strategy_temp_range_t0 = <600 4510 0
								 575 4500 0
								 550 4490 0
								 525 4480 0
								 500 4470 1>;
				strategy_temp_range_t1 = <600 4510 0
								 565 4505 0
								 530 4490 0
								 495 4480 0
								 460 4470 1>;
				strategy_temp_range_t2 = <1910 4540 0
								 1710 4530 0
								 1510 4518 0
								 1310 4492 0
								 1000 4466 1>;
				strategy_temp_range_t3 = <3410 4543 0
								 3210 4536 0
								 2510 4509 0
								 1810 4499 0
								 1000 4479 1>;
				strategy_temp_range_t4 = <3410 4543 0
								 3210 4536 0
								 2510 4509 0
								 1810 4499 0
								 1000 4479 1>;
				strategy_temp_range_t5 = <5100 4536 0
								 4900 4528 0
								 3600 4503 0
								 2300 4487 0
								 1000 4461 1>;
			};
		};

		svooc_charge_strategy {
			strategy_soc_0_to_50 { /* 0 ~ 20 */
				strategy_temp_little_cold =	<4150 27 0 0 0
								 4150 25 0 0 0
								 4150 20 0 0 0
								 4500 15 0 0 0
								 4510 10 1 0 0>;
				strategy_temp_cool = <4150 41 0 0 0
								 4150 40 0 0 0
								 4150 35 0 0 0
								 4150 30 0 0 0
								 4500 27 0 0 0
								 4500 25 0 0 0
								 4500 20 0 0 0
								 4500 15 0 0 0
								 4510 10 1 0 0>;
				strategy_temp_little_cool =	<4230 41 0 0 0
								 4230 40 0 0 0
								 4230 35 0 0 0
								 4230 30 0 0 0
								 4540 27 0 0 0
								 4540 25 0 0 0
								 4540 20 0 0 0
								 4540 15 0 0 0
								 4545 11 1 0 0>;
				strategy_temp_little_cool_high = <4230 41 0 0 0
								 4230 40 0 0 0
								 4230 35 0 0 0
								 4230 30 0 0 0
								 4540 27 0 0 0
								 4540 25 0 0 0
								 4540 20 0 0 0
								 4545 19 1 0 0>;
				strategy_temp_normal_low = <4230 41 0 0 0
								 4230 40 0 0 0
								 4230 35 0 0 0
								 4230 30 0 0 0
								 4540 27 0 0 0
								 4540 25 0 0 0
								 4540 20 0 0 0
								 4545 19 1 0 0>;
				strategy_temp_normal_high =	<4540 41 0 0 0
								 4540 40 0 0 0
								 4540 35 0 0 0
								 4540 30 0 0 0
								 4545 27 1 0 0>;
				strategy_temp_warm = <4120 32 0 0 0
								 4120 30 0 0 0
								 4120 25 0 0 0
								 4120 20 0 0 0
								 4120 15 0 0 0
								 4130 10 1 0 0>;
			};

			strategy_soc_0_to_50_mid { /* 21 ~ 35 */
				strategy_temp_little_cold =	<4150 27 0 0 0
								 4150 25 0 0 0
								 4150 20 0 0 0
								 4500 15 0 0 0
								 4510 10 1 0 0>;
				strategy_temp_cool = <4150 41 0 0 0
								 4150 40 0 0 0
								 4150 35 0 0 0
								 4150 30 0 0 0
								 4500 27 0 0 0
								 4500 25 0 0 0
								 4500 20 0 0 0
								 4500 15 0 0 0
								 4510 10 1 0 0>;
				strategy_temp_little_cool =	<4230 41 0 0 0
								 4230 40 0 0 0
								 4230 35 0 0 0
								 4230 30 0 0 0
								 4540 27 0 0 0
								 4540 25 0 0 0
								 4540 20 0 0 0
								 4540 15 0 0 0
								 4545 11 1 0 0>;
				strategy_temp_little_cool_high = <4230 41 0 0 0
								 4230 40 0 0 0
								 4230 35 0 0 0
								 4230 30 0 0 0
								 4540 27 0 0 0
								 4540 25 0 0 0
								 4540 20 0 0 0
								 4545 19 1 0 0>;
				strategy_temp_normal_low = <4230 41 0 0 0
								 4230 40 0 0 0
								 4230 35 0 0 0
								 4230 30 0 0 0
								 4540 27 0 0 0
								 4540 25 0 0 0
								 4540 20 0 0 0
								 4545 19 1 0 0>;
				strategy_temp_normal_high =	<4540 41 0 0 0
								 4540 40 0 0 0
								 4540 35 0 0 0
								 4540 30 0 0 0
								 4545 27 1 0 0>;
				strategy_temp_warm = <4120 32 0 0 0
								 4120 30 0 0 0
								 4120 25 0 0 0
								 4120 20 0 0 0
								 4120 15 0 0 0
								 4130 10 1 0 0>;
			};

			strategy_soc_0_to_50_high { /* 36 ~ 55 */
				strategy_temp_little_cold =	<4150 20 0 0 0
								 4500 15 0 0 0
								 4510 10 1 0 0>;
				strategy_temp_cool = <4500 25 0 0 0
								 4500 20 0 0 0
								 4500 15 0 0 0
								 4510 10 1 0 0>;
				strategy_temp_little_cool =	<4230 30 0 0 0
								 4540 27 0 0 0
								 4540 25 0 0 0
								 4540 20 0 0 0
								 4540 15 0 0 0
								 4545 11 1 0 0>;
				strategy_temp_little_cool_high = <4230 30 0 0 0
								 4540 27 0 0 0
								 4540 25 0 0 0
								 4540 20 0 0 0
								 4545 19 1 0 0>;
				strategy_temp_normal_low =	<4230 41 0 0 0
								 4230 40 0 0 0
								 4230 35 0 0 0
								 4230 30 0 0 0
								 4540 27 0 0 0
								 4540 25 0 0 0
								 4540 20 0 0 0
								 4545 19 1 0 0>;
				strategy_temp_normal_high =	<4540 41 0 0 0
								 4540 40 0 0 0
								 4540 35 0 0 0
								 4540 30 0 0 0
								 4545 27 1 0 0>;
				strategy_temp_warm = <4120 32 0 0 0
								 4120 30 0 0 0
								 4120 25 0 0 0
								 4120 20 0 0 0
								 4120 15 0 0 0
								 4130 10 1 0 0>;
			};

			strategy_soc_50_to_75 { /* 56 ~ 75 */
				strategy_temp_little_cold =	<4510 10 1 0 0>;
				strategy_temp_cool = <4500 15 0 0 0
								 4510 10 1 0 0>;
				strategy_temp_little_cool =	<4540 20 0 0 0
								 4540 15 0 0 0
								 4545 11 1 0 0>;
				strategy_temp_little_cool_high = <4540 20 0 0 0
								 4545 19 1 0 0>;
				strategy_temp_normal_low = <4540 25 0 0 0
								 4540 20 0 0 0
								 4545 19 1 0 >;
				strategy_temp_normal_high =	<4540 30 0 0 0
								 4545 27 1 0 0>;
				strategy_temp_warm = <4130 10 1 0 0>;
			};

			strategy_soc_75_to_85 {	/*76 ~ 85*/
				strategy_temp_little_cold =	<4510 10 1 0 0>;
				strategy_temp_cool = <4510 10 1 0 0>;
				strategy_temp_little_cool =	<4540 15 0 0 0
								 4545 11 1 0 0>;
				strategy_temp_little_cool_high = <4545 19 1 0 0>;
				strategy_temp_normal_low = <4540 20 0 0 0
								 4545 19 1 0 0>;
				strategy_temp_normal_high =	<4545 27 1 0 0>;
				strategy_temp_warm = <4130 10 1 0 0>;
			};

			strategy_soc_85_to_90 { /*86 ~ 95*/
				strategy_temp_little_cold =	<4510 10 1 0 0>;
				strategy_temp_cool = <4510 10 1 0 0>;
				strategy_temp_little_cool =	<4545 11 1 0 0>;
				strategy_temp_little_cool_high = <4545 19 1 0 0>;
				strategy_temp_normal_low = <4540 20 0 0 0
								 4545 19 1 0 0>;
				strategy_temp_normal_high =	<4545 27 1 0 0>;
				strategy_temp_warm = <4130 10 1 0 0>;
			};
		};

		vooc_charge_strategy {
			strategy_soc_0_to_50 {
				strategy_temp_little_cold =	<4150 30 0 0 0
								 4510 28 0 0 0
								 4520 20 1 0 0>;
				strategy_temp_cool = <4510 30 0 0 0
								 4520 20 1 0 0>;
				strategy_temp_little_cool =	<4540 30 0 0 0
								 4550 20 1 0 0>;
				strategy_temp_little_cool_high = <4540 30 0 0 0
								 4550 20 1 0 0>;
				strategy_temp_normal_low = <4540 30 0 0 0
								 4550 20 1 0 0>;
				strategy_temp_normal_high =	<4540 30 0 0 0
								 4550 20 1 0 0>;
				strategy_temp_warm = <4120 30 0 0 0
								 4130 20 1 0 0>;
			};

			strategy_soc_0_to_50_mid {
				strategy_temp_little_cold =	<4150 30 0 0 0
								 4510 28 0 0 0
								 4520 20 1 0 0>;
				strategy_temp_cool = <4510 30 0 0 0
								 4520 20 1 0 0>;
				strategy_temp_little_cool =	<4540 30 0 0 0
								 4550 20 1 0 0>;
				strategy_temp_little_cool_high = <4540 30 0 0 0
								 4550 20 1 0 0>;
				strategy_temp_normal_low = <4540 30 0 0 0
								 4550 20 1 0 0>;
				strategy_temp_normal_high =	<4540 30 0 0 0
								 4550 20 1 0 0>;
				strategy_temp_warm = <4120 30 0 0 0
								 4130 20 1 0 0>;
			};

			strategy_soc_0_to_50_high {
				strategy_temp_little_cold =	<4150 30 0 0 0
								 4510 28 0 0 0
								 4520 20 1 0 0>;
				strategy_temp_cool = <4510 30 0 0 0
								 4520 20 1 0 0>;
				strategy_temp_little_cool =	<4540 30 0 0 0
								 4550 20 1 0 0>;
				strategy_temp_little_cool_high = <4540 30 0 0 0
								 4550 20 1 0 0>;
				strategy_temp_normal_low = <4540 30 0 0 0
								 4550 20 1 0 0>;
				strategy_temp_normal_high =	<4540 30 0 0 0
								 4550 20 1 0 0>;
				strategy_temp_warm = <4120 30 0 0 0
								 4130 20 1 0 0>;
			};

			strategy_soc_50_to_75 {
				strategy_temp_little_cold =	<4520 20 1 0 0>;
				strategy_temp_cool = <4510 30 0 0 0
								 4520 20 1 0 0>;
				strategy_temp_little_cool =	<4540 30 0 0 0
								 4550 20 1 0 0>;
				strategy_temp_little_cool_high = <4540 30 0 0 0
								 4550 20 1 0 0>;
				strategy_temp_normal_low = <4540 30 0 0 0
								 4550 20 1 0 0>;
				strategy_temp_normal_high =	<4540 30 0 0 0
								 4550 20 1 0 0>;
				strategy_temp_warm = <4130 20 1 0 0>;
			};

			strategy_soc_75_to_85 {
				strategy_temp_little_cold =	<4520 20 1 0 0>;
				strategy_temp_cool = <4520 20 1 0 0>;
				strategy_temp_little_cool =	<4540 30 0 0 0
								 4550 20 1 0 0>;
				strategy_temp_little_cool_high = <4540 30 0 0 0
								 4550 20 1 0 0>;
				strategy_temp_normal_low = <4540 30 0 0 0
								 4550 20 1 0 0>;
				strategy_temp_normal_high =	<4540 30 0 0 0
								 4550 20 1 0 0>;
				strategy_temp_warm = <4130 20 1 0 0>;
			};

			strategy_soc_85_to_90 {
				strategy_temp_little_cold =	<4520 20 1 0 0>;
				strategy_temp_cool = <4520 20 1 0 0>;
				strategy_temp_little_cool =	<4550 20 1 0 0>;
				strategy_temp_little_cool_high = <4550 20 1 0 0>;
				strategy_temp_normal_low = <4550 20 1 0 0>;
				strategy_temp_normal_high =	<4550 20 1 0 0>;
				strategy_temp_warm = <4130 20 1 0 0>;
			};
		};

		oplus_sc8547_cp: oplus,sc8547_cp {
			oplus,ic_type = <OPLUS_CHG_IC_CP>;
			oplus,ic_index = <0>;
			oplus,ic_func_group = <&sc8547_cp_groups>;
		};
	};
};

//ifdef OPLUS_FEATURE_CHG_BASIC
&oplus_cpa {
	oplus,cpa_region_cfg_pps {
		oplus,region_id = /bits/ 8 <0x00 0x44 0x83 0x5a>; /* t0 machine: 0x00, europe: 0x44 Saudi Arabia: 0x83  Serbia: 0x5a*/
		oplus,protocol_list = <CHG_PROTOCOL_VOOC 45
					CHG_PROTOCOL_PPS  45
					CHG_PROTOCOL_PD   15>;
		oplus,default_protocol_list = <CHG_PROTOCOL_VOOC
					CHG_PROTOCOL_PPS
					CHG_PROTOCOL_PD>;
	};
};

&charger {
	oplus_ap_pps: oplus,ap_pps {
		oplus,ic_type = <OPLUS_CHG_IC_PPS>;
		oplus,ic_index = <0>;
	};
};

&soc {
	oplus_virtual_pps: oplus,virtual_pps {
		compatible = "oplus,virtual_pps";

		oplus,ic_type = <OPLUS_CHG_IC_VIRTUAL_PPS>;
		oplus,ic_index = <0>;
		oplus,pps_ic = <&oplus_ap_pps>;
	};
	oplus_pps_charge: oplus,pps_charge {
		compatible = "oplus,pps_charge";
		oplus,pps_ic = <&oplus_virtual_pps>;
		oplus,cp_ic = <&oplus_virtual_cp>;
		oplus,dpdm_switch_ic = <&oplus_virtual_dpdm_switch>;

		oplus,target_vbus_mv = <11000>;
		oplus,curr_max_ma = <4100>;
		oplus,curr_max_ma_percent = <4100 /* 75% ibus */
					     2000 /* 85% ibus */>;
		oplus,pps_warm_allow_vol = <4000>;
		oplus,pps_warm_allow_soc = <55>;
		oplus,pps_strategy_normal_current = <4100>;
		oplus,pps_over_high_or_low_current = <4100>;
		oplus,pps_timeout_third = <30612>;
		oplus,pps_timeout_oplus = <30612>;
		oplus,pps_ibat_over_third = <9600>;
		oplus,pps_ibat_over_oplus = <9600>;
		oplus,pps_full_cool_sw_vbat = <4490>;
		oplus,pps_full_normal_sw_vbat = <4490>;
		oplus,pps_full_normal_hw_vbat = <4500>;
		oplus,pps_full_ffc_vbat = <4485>;
		oplus,pps_full_warm_vbat = <4130>;
		oplus,pps_full_cool_sw_vbat_third = <4490>;
		oplus,pps_full_normal_sw_vbat_third= <4490>;
		oplus,pps_full_normal_hw_vbat_third = <4500>;
		oplus,pps_current_change_timeout = <100>;
		oplus,pps_r_default = <270 45 10 45 20 20 20>;
		oplus,pps_rmos_mohm = <5>;
		oplus,pps_r_limit = <150 100 80 70 30>;
		oplus,pps_little_cool_high_temp = <210>;
		oplus,curve_strategy_name = "pps_ufcs_curve_v2";
		oplus,pps_strategy_batt_high_temp = <410 420 430 400 410 420>;
		oplus,pps_strategy_high_current = <5000 4000 4000 5000 5000 5000>;
		oplus,pps_charge_strategy_soc = <0 20 35 55 75 85 95>;
		oplus,pps_charge_strategy_temp = <0 50 120 160 350 440 510>;
		oplus,pps_low_curr_full_strategy_temp = <0 200 350 440>;

		oplus,temperature_strategy_name = "cgcl";
 		oplus,temperature_strategy_data = <OPLUS_STRATEGY_USE_SHELL_TEMP
						0   385 4100 1 0
 						375 405 3500 2 0
 						395 420 2500 3 1
 						410 430 2000 4 2
						425 440 1500 4 3>;
		oplus,plc_strategy-data = <&pps_simple_strategy>;
		oplus,plc_strategy-names = "default";

		pps_third_lcf_strategy {
			oplus,temp_type = <OPLUS_STRATEGY_USE_SHELL_TEMP>;
			oplus,temp_range = <0 50 120 160 210 380 440>;

			strategy_temp_range_curves {
				strategy_temp_range_t0 = <600 4510 0
								 575 4500 0
								 550 4490 0
								 525 4480 0
								 500 4470 1>;
				strategy_temp_range_t1 = <600 4510 0
								 565 4505 0
								 530 4490 0
								 495 4480 0
								 460 4470 1>;
				strategy_temp_range_t2 = <1910 4540 0
								 1710 4530 0
								 1510 4518 0
								 1310 4492 0
								 1000 4466 1>;
				strategy_temp_range_t3 = <3410 4543 0
								 3210 4536 0
								 2510 4509 0
								 1810 4499 0
								 1000 4479 1>;
				strategy_temp_range_t4 = <3410 4543 0
								 3210 4536 0
								 2510 4509 0
								 1810 4499 0
								 1000 4479 1>;
				strategy_temp_range_t5 = <5100 4536 0
								 4900 4528 0
								 3600 4503 0
								 2300 4487 0
								 1000 4461 1>;
			};
		};

		pps_oplus_lcf_strategy {
			oplus,temp_type = <OPLUS_STRATEGY_USE_SHELL_TEMP>;
			oplus,temp_range = <0 50 120 160 210 380 440>;

			strategy_temp_range_curves {
				strategy_temp_range_t0 = <600 4510 0
								 575 4500 0
								 550 4490 0
								 525 4480 0
								 500 4470 1>;
				strategy_temp_range_t1 = <600 4510 0
								 565 4505 0
								 530 4490 0
								 495 4480 0
								 460 4470 1>;
				strategy_temp_range_t2 = <1910 4540 0
								 1710 4530 0
								 1510 4518 0
								 1310 4492 0
								 1000 4466 1>;
				strategy_temp_range_t3 = <3410 4543 0
								 3210 4536 0
								 2510 4509 0
								 1810 4499 0
								 1000 4479 1>;
				strategy_temp_range_t4 = <3410 4543 0
								 3210 4536 0
								 2510 4509 0
								 1810 4499 0
								 1000 4479 1>;
				strategy_temp_range_t5 = <5100 4536 0
								 4900 4528 0
								 3600 4503 0
								 2300 4487 0
								 1000 4461 1>;
			};
		};

		pps_charge_third_strategy {
			oplus,temp_type = <OPLUS_STRATEGY_USE_SHELL_TEMP>;
			oplus,soc_range = <0 20 35 55 75 85 95>;
			oplus,temp_range = <0 50 120 160 210 350 440 530>;

			strategy_soc_range_min { /* ui_soc: 0%~20% */
				strategy_temp_little_cold =	<11000 4150 2700 0 0
								11000 4150 2500 0 0
								11000 4150 2000 0 0
								11000 4480 1500 0 0
								11000 4490 1000 1 0>;
				strategy_temp_cool = <11000 4150 4100 0 0
								11000 4150 4000 0 0
								11000 4150 3500 0 0
								11000 4150 3000 0 0
								11000 4480 2700 0 0
								11000 4480 2500 0 0
								11000 4480 2000 0 0
								11000 4480 1500 0 0
								11000 4490 1000 1 0>;
				strategy_temp_little_cool =	<11000 4230 4100 0 0
								11000 4230 4000 0 0
								11000 4230 3500 0 0
								11000 4230 3000 0 0
								11000 4480 2700 0 0
								11000 4480 2500 0 0
								11000 4480 2000 0 0
								11000 4480 1500 0 0
								11000 4490 1000 1 0>;
				strategy_temp_little_cool_high = <11000 4230 4100 0 0
								11000 4230 4000 0 0
								11000 4230 3500 0 0
								11000 4230 3000 0 0
								11000 4480 2700 0 0
								11000 4480 2500 0 0
								11000 4480 2000 0 0
								11000 4480 1500 0 0
								11000 4490 1000 1 0>;
				strategy_temp_normal_low = <11000 4230 4100 0 0
								11000 4230 4000 0 0
								11000 4230 3500 0 0
								11000 4230 3000 0 0
								11000 4480 2700 0 0
								11000 4480 2500 0 0
								11000 4480 2000 0 0
								11000 4480 1500 0 0
								11000 4490 1000 1 0>;
				strategy_temp_normal_high =	<11000 4460 4100 0 0
								11000 4460 4000 0 0
								11000 4460 3500 0 0
								11000 4460 3000 0 0
								11000 4460 2500 0 0
								11000 4460 2000 0 0
								11000 4460 1500 0 0
								11000 4470 1000 1 0>;
				strategy_temp_warm = <11000 4120 3250 0 0
								11000 4120 3000 0 0
								11000 4120 2500 0 0
								11000 4120 2000 0 0
								11000 4120 1500 0 0
								11000 4130 1000 1 0>;
			};
			strategy_soc_range_low { /* ui_soc: 21%~35% */
				strategy_temp_little_cold =	<11000 4150 2700 0 0
								11000 4150 2500 0 0
								11000 4150 2000 0 0
								11000 4480 1500 0 0
								11000 4490 1000 1 0>;
				strategy_temp_cool = <11000 4150 4100 0 0
								11000 4150 4000 0 0
								11000 4150 3500 0 0
								11000 4150 3000 0 0
								11000 4480 2700 0 0
								11000 4480 2500 0 0
								11000 4480 2000 0 0
								11000 4480 1500 0 0
								11000 4490 1000 1 0>;
				strategy_temp_little_cool =	<11000 4230 4100 0 0
								11000 4230 4000 0 0
								11000 4230 3500 0 0
								11000 4230 3000 0 0
								11000 4480 2700 0 0
								11000 4480 2500 0 0
								11000 4480 2000 0 0
								11000 4480 1500 0 0
								11000 4490 1000 1 0>;
				strategy_temp_little_cool_high = <11000 4230 4100 0 0
								11000 4230 4000 0 0
								11000 4230 3500 0 0
								11000 4230 3000 0 0
								11000 4480 2700 0 0
								11000 4480 2500 0 0
								11000 4480 2000 0 0
								11000 4480 1500 0 0
								11000 4490 1000 1 0>;
				strategy_temp_normal_low = <11000 4230 4100 0 0
								11000 4230 4000 0 0
								11000 4230 3500 0 0
								11000 4230 3000 0 0
								11000 4480 2700 0 0
								11000 4480 2500 0 0
								11000 4480 2000 0 0
								11000 4480 1500 0 0
								11000 4490 1000 1 0>;
				strategy_temp_normal_high =	<11000 4460 4100 0 0
								11000 4460 4000 0 0
								11000 4460 3500 0 0
								11000 4460 3000 0 0
								11000 4460 2500 0 0
								11000 4460 2000 0 0
								11000 4460 1500 0 0
								11000 4470 1000 1 0>;
				strategy_temp_warm = <11000 4120 3250 0 0
								11000 4120 3000 0 0
								11000 4120 2500 0 0
								11000 4120 2000 0 0
								11000 4120 1500 0 0
								11000 4130 1000 1 0>;
			};
			strategy_soc_range_mid_low { /* ui_soc: 36%~55% */
				strategy_temp_little_cold =	<11000 4150 2000 0 0
								11000 4480 1500 0 0
								11000 4490 1000 1 0>;
				strategy_temp_cool = <11000 4480 2500 0 0
								11000 4480 2000 0 0
								11000 4480 1500 0 0
								11000 4490 1000 1 0>;
				strategy_temp_little_cool =	<11000 4230 3000 0 0
								11000 4480 2700 0 0
								11000 4480 2500 0 0
								11000 4480 2000 0 0
								11000 4480 1500 0 0
								11000 4490 1000 1 0>;
				strategy_temp_little_cool_high = <11000 4230 3000 0 0
								11000 4480 2700 0 0
								11000 4480 2500 0 0
								11000 4480 2000 0 0
								11000 4480 1500 0 0
								11000 4490 1000 1 0>;
				strategy_temp_normal_low = <11000 4230 4100 0 0
								11000 4230 4000 0 0
								11000 4230 3500 0 0
								11000 4230 3000 0 0
								11000 4480 2700 0 0
								11000 4480 2500 0 0
								11000 4480 2000 0 0
								11000 4480 1500 0 0
								11000 4490 1000 1 0>;
				strategy_temp_normal_high =	<11000 4460 4100 0 0
								11000 4460 4000 0 0
								11000 4460 3500 0 0
								11000 4460 3000 0 0
								11000 4460 2500 0 0
								11000 4460 2000 0 0
								11000 4460 1500 0 0
								11000 4470 1000 1 0>;
				strategy_temp_warm = <11000 4120 3250 0 0
								11000 4120 3000 0 0
								11000 4120 2500 0 0
								11000 4120 2000 0 0
								11000 4120 1500 0 0
								11000 4130 1000 1 0>;
			};
			strategy_soc_range_mid { /* ui_soc: 56%~75% */
				strategy_temp_little_cold =	<11000 4490 1000 1 0>;
				strategy_temp_cool = <11000 4480 1500 0 0
								11000 4490 1000 1 0>;
				strategy_temp_little_cool =	<11000 4480 2000 0 0
								11000 4480 1500 0 0
								11000 4490 1000 1 0>;
				strategy_temp_little_cool_high = <11000 4480 2000 0 0
								11000 4480 1500 0 0
								11000 4490 1000 1 0>;
				strategy_temp_normal_low = <11000 4480 2500 0 0
								11000 4480 2000 0 0
								11000 4480 1500 0 0
								11000 4490 1000 1 0>;
				strategy_temp_normal_high =	<11000 4460 3000 0 0
								11000 4460 2500 0 0
								11000 4460 2000 0 0
								11000 4460 1500 0 0
								11000 4470 1000 1 0>;
				strategy_temp_warm = <11000 4130 1000 1 0>;
			};
			strategy_soc_range_mid_high { /* ui_soc: 76%~85% */
				strategy_temp_little_cold =	<11000 4490 1000 1 0>;
				strategy_temp_cool = <11000 4490 1000 1 0>;
				strategy_temp_little_cool =	<11000 4480 1500 0 0
								11000 4490 1000 1 0>;
				strategy_temp_little_cool_high = <11000 4480 1500 0 0
								11000 4490 1000 1 0>;
				strategy_temp_normal_low = <11000 4480 2000 0 0
								11000 4480 1500 0 0
								11000 4490 1000 1 0>;
				strategy_temp_normal_high =	<11000 4460 2500 0 0
								11000 4460 2000 0 0
								11000 4460 1500 0 0
								11000 4470 1000 1 0>;
				strategy_temp_warm = <11000 4130 1000 1 0>;
			};
			strategy_soc_range_high { /* ui_soc: 86%~90% */
				strategy_temp_little_cold =	<11000 4490 1000 1 0>;
				strategy_temp_cool = <11000 4490 1000 1 0>;
				strategy_temp_little_cool =	<11000 4490 1000 1 0>;
				strategy_temp_little_cool_high = <11000 4480 1500 0 0
								11000 4490 1000 1 0>;
				strategy_temp_normal_low = <11000 4480 2000 0 0
								11000 4480 1500 0 0
								11000 4490 1000 1 0>;
				strategy_temp_normal_high =	<11000 4460 2000 0 0
								11000 4460 1500 0 0
								11000 4470 1000 1 0>;
				strategy_temp_warm = <11000 4130 1000 1 0>;
			};
		};

		pps_charge_oplus_strategy {
			oplus,temp_type = <OPLUS_STRATEGY_USE_SHELL_TEMP>;
			oplus,soc_range = <0 20 35 55 75 85 95>;
			oplus,temp_range = <0 50 120 160 210 350 440 530>;

			strategy_soc_range_min { /* ui_soc: 0%~20% */
				strategy_temp_little_cold =	<11000 4150 2700 0 0
								11000 4150 2500 0 0
								11000 4150 2000 0 0
								11000 4480 1500 0 0
								11000 4490 1000 1 0>;
				strategy_temp_cool = <11000 4150 4100 0 0
								11000 4150 4000 0 0
								11000 4150 3500 0 0
								11000 4150 3000 0 0
								11000 4480 2700 0 0
								11000 4480 2500 0 0
								11000 4480 2000 0 0
								11000 4480 1500 0 0
								11000 4490 1000 1 0>;
				strategy_temp_little_cool =	<11000 4230 4100 0 0
								11000 4230 4000 0 0
								11000 4230 3500 0 0
								11000 4230 3000 0 0
								11000 4480 2700 0 0
								11000 4480 2500 0 0
								11000 4480 2000 0 0
								11000 4480 1500 0 0
								11000 4490 1000 1 0>;
				strategy_temp_little_cool_high = <11000 4230 4100 0 0
								11000 4230 4000 0 0
								11000 4230 3500 0 0
								11000 4230 3000 0 0
								11000 4480 2700 0 0
								11000 4480 2500 0 0
								11000 4480 2000 0 0
								11000 4480 1500 0 0
								11000 4490 1000 1 0>;
				strategy_temp_normal_low = <11000 4230 4100 0 0
								11000 4230 4000 0 0
								11000 4230 3500 0 0
								11000 4230 3000 0 0
								11000 4480 2700 0 0
								11000 4480 2500 0 0
								11000 4480 2000 0 0
								11000 4480 1500 0 0
								11000 4490 1000 1 0>;
				strategy_temp_normal_high =	<11000 4460 4100 0 0
								11000 4460 4000 0 0
								11000 4460 3500 0 0
								11000 4460 3000 0 0
								11000 4460 2500 0 0
								11000 4460 2000 0 0
								11000 4460 1500 0 0
								11000 4470 1000 1 0>;
				strategy_temp_warm = <11000 4120 3250 0 0
								11000 4120 3000 0 0
								11000 4120 2500 0 0
								11000 4120 2000 0 0
								11000 4120 1500 0 0
								11000 4130 1000 1 0>;
			};
			strategy_soc_range_low { /* ui_soc: 21%~35% */
				strategy_temp_little_cold =	<11000 4150 2700 0 0
								11000 4150 2500 0 0
								11000 4150 2000 0 0
								11000 4480 1500 0 0
								11000 4490 1000 1 0>;
				strategy_temp_cool = <11000 4150 4100 0 0
								11000 4150 4000 0 0
								11000 4150 3500 0 0
								11000 4150 3000 0 0
								11000 4480 2700 0 0
								11000 4480 2500 0 0
								11000 4480 2000 0 0
								11000 4480 1500 0 0
								11000 4490 1000 1 0>;
				strategy_temp_little_cool =	<11000 4230 4100 0 0
								11000 4230 4000 0 0
								11000 4230 3500 0 0
								11000 4230 3000 0 0
								11000 4480 2700 0 0
								11000 4480 2500 0 0
								11000 4480 2000 0 0
								11000 4480 1500 0 0
								11000 4490 1000 1 0>;
				strategy_temp_little_cool_high = <11000 4230 4100 0 0
								11000 4230 4000 0 0
								11000 4230 3500 0 0
								11000 4230 3000 0 0
								11000 4480 2700 0 0
								11000 4480 2500 0 0
								11000 4480 2000 0 0
								11000 4480 1500 0 0
								11000 4490 1000 1 0>;
				strategy_temp_normal_low = <11000 4230 4100 0 0
								11000 4230 4000 0 0
								11000 4230 3500 0 0
								11000 4230 3000 0 0
								11000 4480 2700 0 0
								11000 4480 2500 0 0
								11000 4480 2000 0 0
								11000 4480 1500 0 0
								11000 4490 1000 1 0>;
				strategy_temp_normal_high =	<11000 4460 4100 0 0
								11000 4460 4000 0 0
								11000 4460 3500 0 0
								11000 4460 3000 0 0
								11000 4460 2500 0 0
								11000 4460 2000 0 0
								11000 4460 1500 0 0
								11000 4470 1000 1 0>;
				strategy_temp_warm = <11000 4120 3350 0 0
								11000 4120 3000 0 0
								11000 4120 2500 0 0
								11000 4120 2000 0 0
								11000 4120 1500 0 0
								11000 4130 1000 1 0>;
			};
			strategy_soc_range_mid_low { /* ui_soc: 36%~55% */
				strategy_temp_little_cold =	<11000 4150 2000 0 0
								11000 4480 1500 0 0
								11000 4490 1000 1 0>;
				strategy_temp_cool = <11000 4480 2500 0 0
								11000 4480 2000 0 0
								11000 4480 1500 0 0
								11000 4490 1000 1 0>;
				strategy_temp_little_cool =	<11000 4230 3000 0 0
								11000 4480 2700 0 0
								11000 4480 2500 0 0
								11000 4480 2000 0 0
								11000 4480 1500 0 0
								11000 4490 1000 1 0>;
				strategy_temp_little_cool_high = <11000 4230 3000 0 0
								11000 4480 2700 0 0
								11000 4480 2500 0 0
								11000 4480 2000 0 0
								11000 4480 1500 0 0
								11000 4490 1000 1 0>;
				strategy_temp_normal_low = <11000 4230 4100 0 0
								11000 4230 4000 0 0
								11000 4230 3500 0 0
								11000 4230 3000 0 0
								11000 4480 2700 0 0
								11000 4480 2500 0 0
								11000 4480 2000 0 0
								11000 4480 1500 0 0
								11000 4490 1000 1 0>;
				strategy_temp_normal_high =	<11000 4460 4100 0 0
								11000 4460 4000 0 0
								11000 4460 3500 0 0
								11000 4460 3000 0 0
								11000 4460 2500 0 0
								11000 4460 2000 0 0
								11000 4460 1500 0 0
								11000 4470 1000 1 0>;
				strategy_temp_warm = <11000 4120 3250 0 0
								11000 4120 3000 0 0
								11000 4120 2500 0 0
								11000 4120 2000 0 0
								11000 4120 1500 0 0
								11000 4130 1000 1 0>;
			};
			strategy_soc_range_mid { /* ui_soc: 56%~75% */
				strategy_temp_little_cold =	<11000 4490 1000 1 0>;
				strategy_temp_cool = <11000 4480 1500 0 0
								11000 4490 1000 1 0>;
				strategy_temp_little_cool =	<11000 4480 2000 0 0
								11000 4480 1500 0 0
								11000 4490 1000 1 0>;
				strategy_temp_little_cool_high = <11000 4480 2000 0 0
								11000 4480 1500 0 0
								11000 4490 1000 1 0>;
				strategy_temp_normal_low = <11000 4480 2500 0 0
								11000 4480 2000 0 0
								11000 4480 1500 0 0
								11000 4490 1000 1 0>;
				strategy_temp_normal_high =	<11000 4460 3000 0 0
								11000 4460 2500 0 0
								11000 4460 2000 0 0
								11000 4460 1500 0 0
								11000 4470 1000 1 0>;
				strategy_temp_warm = <11000 4130 1000 1 0>;
			};
			strategy_soc_range_mid_high { /* ui_soc: 76%~85% */
				strategy_temp_little_cold =	<11000 4490 1000 1 0>;
				strategy_temp_cool = <11000 4490 1000 1 0>;
				strategy_temp_little_cool =	<11000 4480 1500 0 0
								11000 4490 1000 1 0>;
				strategy_temp_little_cool_high = <11000 4480 1500 0 0
								11000 4490 1000 1 0>;
				strategy_temp_normal_low = <11000 4480 2000 0 0
								11000 4480 1500 0 0
								11000 4490 1000 1 0>;
				strategy_temp_normal_high =	<11000 4460 2500 0 0
								11000 4460 2000 0 0
								11000 4460 1500 0 0
								11000 4470 1000 1 0>;
				strategy_temp_warm = <11000 4130 1000 1 0>;
			};
			strategy_soc_range_high { /* ui_soc: 86%~90% */
				strategy_temp_little_cold =	<11000 4490 1000 1 0>;
				strategy_temp_cool = <11000 4490 1000 1 0>;
				strategy_temp_little_cool =	<11000 4490 1000 1 0>;
				strategy_temp_little_cool_high = <11000 4480 1500 0 0
								11000 4490 1000 1 0>;
				strategy_temp_normal_low = <11000 4480 2000 0 0
								11000 4480 1500 0 0
								11000 4490 1000 1 0>;
				strategy_temp_normal_high =	<11000 4460 2000 0 0
								11000 4460 1500 0 0
								11000 4470 1000 1 0>;
				strategy_temp_warm = <11000 4130 1000 1 0>;
			};
		};
	};
};
//#endif OPLUS_FEATURE_CHG_BASIC

